# TB1_367.0_inst3 register map
Vendor: Texas Instruments
Peripheral module from a debugger description file (folder msp430).
Registers are 16-bit, access not given, no defined reset value unless marked. A register's access mark holds for its fields unless they carry their own. Offsets are as the file gives them; lines under a group give offsets from that group; [hi:lo] are bit positions; {n}, {i} and the like mark numbered series; 'fields as' and 'values as' point back to an identical list; <NAME> marks a mode.

## TB1
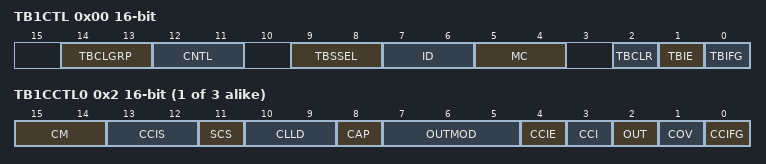
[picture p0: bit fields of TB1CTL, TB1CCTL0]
0x00 TB1CTL rw — Timer_B Control Register
  [14:13] TBCLGRP — TBxCLn group
    0=Each TBxCLn latch loads independently; 1=TBxCL1+TBxCL2 (TBxCCR1 CLLD bits control the update); TBxCL3+TBxCL4 (TBxCCR3 CLLD bits control the update); TBxCL5+TBxCL6 (TBxCCR5 CLLD bits control the update); TBxCL0 independent; 2=TBxCL1+TBxCL2+TBxCL3 (TBxCCR1 CLLD bits control the update); TBxCL4+TBxCL5+TBxCL6 (TBxCCR4 CLLD bits control the update); TBxCL0 independent; 3=TBxCL0+TBxCL1+TBxCL2+TBxCL3+TBxCL4+TBxCL5+TBxCL6 (TBxCCR1 CLLD bits control the update)
  [12:11] CNTL — Counter length
    0=16-bit, TBxR(max) = 0FFFFh; 1=12-bit, TBxR(max) = 0FFFh; 2=10-bit, TBxR(max) = 03FFh; 3=8-bit, TBxR(max) = 0FFh
  [9:8] TBSSEL — TimerB clock source select
    0=TBCLK (TBxCLK); 1=ACLK; 2=SMCLK; 3=INCLK
  [7:6] ID — Input divider
    0=1; 1=2; 2=4; 3=8
  [5:4] MC — Mode control
    0=STOP (Stop mode: Timer is halted); 1=UP (Up mode: Timer counts up to TBxCL0); 2=CONTINUOUS (Continuous mode: Timer counts up to the value set by CNTL); 3=UPDOWN (Up/down mode: Timer counts up to TBxCL0 then down to 0000h)
  [2] TBCLR — TimerB clear
  [1] TBIE — TimerB interrupt enable
    0=Interrupt disabled; 1=Interrupt enabled
  [0] TBIFG — TimerB interrupt flag
    0=No interrupt pending; 1=Interrupt pending
{0x2+2i} TB1CCTL{i} access per field (i=0..2) — Timer_B Capture/Compare Control Register
  [15:14] CM rw — Capture mode
    0=NONE (No capture); 1=RISING (Capture on rising edge); 2=FALLING (Capture on falling edge); 3=BOTH (Capture on both rising and falling edges)
  [13:12] CCIS rw — Capture/compare input select
    0=CCIA (CCIxA); 1=CCIB (CCIxB); 2=GND; 3=VCC
  [11] SCS rw — Synchronize capture source
    0=ASYNC (Asynchronous capture); 1=SYNC (Synchronous capture)
  [10:9] CLLD rw — Compare latch load
    0=TBxCLn loads on write to TBxCCRn; 1=TBxCLn loads when TBxR counts to 0; 2=TBxCLn loads when TBxR counts to 0 (up or continuous mode). TBxCLn loads when TBxR counts to TBxCL0 or to 0 (up/down mode).; 3=TBxCLn loads when TBxR counts to TBxCLn
  [8] CAP rw — Capture mode
    0=COMPARE (Compare mode); 1=CAPTURE (Capture mode)
  [7:5] OUTMOD rw — Output mode
    0=OUT bit value; 1=Set; 2=Toggle/reset; 3=Set/reset; 4=Toggle; 5=Reset; 6=Toggle/set; 7=Reset/set
  [4] CCIE rw — Capture/compare interrupt enable
    0=Interrupt disabled; 1=Interrupt enabled
  [3] CCI ro — Capture/compare input
  [2] OUT rw — Output
    0=LOW (Output low); 1=HIGH (Output high)
  [1] COV rw — Capture overflow
    0=No capture overflow occurred; 1=Capture overflow occurred
  [0] CCIFG rw — Capture/compare interrupt flag
    0=No interrupt pending; 1=Interrupt pending
0x10 TB1R — Timer_B count register
{0x12+2i} TB1CCR{i} (i=0..2) — Timer_B Capture/Compare Register
0x20 TB1EX0 rw — Timer_Bx Expansion Register 0
  [2:0] TBIDEX — Input divider expansion
    {v}=Divide by {v+1} (v=0..7)
0x2E TB1IV ro — Timer_Bx Interrupt Vector Register
  [15:0] TBIV — Timer_B interrupt vector value
    0=NONE (No interrupt pending); 2=TBCCR1 (Interrupt Source: Capture/compare 1; Interrupt Flag: TBxCCR1 CCIFG; Interrupt Priority: Highest); 4=TBCCR2 (Interrupt Source: Capture/compare 2; Interrupt Flag: TBxCCR2 CCIFG); 6=TBCCR3 (Interrupt Source: Capture/compare 3; Interrupt Flag: TBxCCR3 CCIFG); 8=TBCCR4 (Interrupt Source: Capture/compare 4; Interrupt Flag: TBxCCR4 CCIFG); 10=TBCCR5 (Interrupt Source: Capture/compare 5; Interrupt Flag: TBxCCR5 CCIFG); 12=TBCCR6 (Interrupt Source: Capture/compare 6; Interrupt Flag: TBxCCR6 CCIFG); 14=TBIFG (Interrupt Source: Timer overflow; Interrupt Flag: TBxCTL TBIFG; Interrupt Priority: Lowest)
